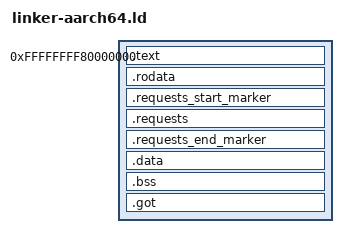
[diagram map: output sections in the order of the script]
/* TrustOS Kernel Linker Script - aarch64 (ARM64)
 * Limine bootloader, higher-half kernel
 * Mirrors the x86_64 linker script layout for compatibility with rust-lld.
 */

OUTPUT_FORMAT(elf64-littleaarch64)
OUTPUT_ARCH(aarch64)
ENTRY(kmain)

PHDRS
{
    text    PT_LOAD FLAGS(5);   /* R-X */
    rodata  PT_LOAD FLAGS(4);   /* R-- */
    data    PT_LOAD FLAGS(6);   /* RW- */
}

SECTIONS
{
    . = 0xffffffff80000000;

    .text : {
        __text_start = .;
        KEEP(*(.text.kmain))
        *(.text .text.*)
        __text_end = .;
    } :text

    . = ALIGN(CONSTANT(MAXPAGESIZE));

    .rodata : {
        __rodata_start = .;
        *(.rodata .rodata.*)
    } :rodata

    /* Limine requests sections — must be in rodata for Limine to find them */
    .requests_start_marker : {
        KEEP(*(.requests_start_marker))
    } :rodata

    .requests : {
        KEEP(*(.requests))
    } :rodata

    .requests_end_marker : {
        KEEP(*(.requests_end_marker))
    } :rodata

    __rodata_end = .;

    . = ALIGN(CONSTANT(MAXPAGESIZE));

    .data : {
        *(.data .data.*)
    } :data

    .bss : {
        __bss_start = .;
        *(.bss .bss.*)
        *(COMMON)
        __bss_end = .;
    } :data

    .got : {
        *(.got .got.*)
    } :data

    /DISCARD/ : {
        *(.eh_frame*)
        *(.note .note.*)
    }
}
